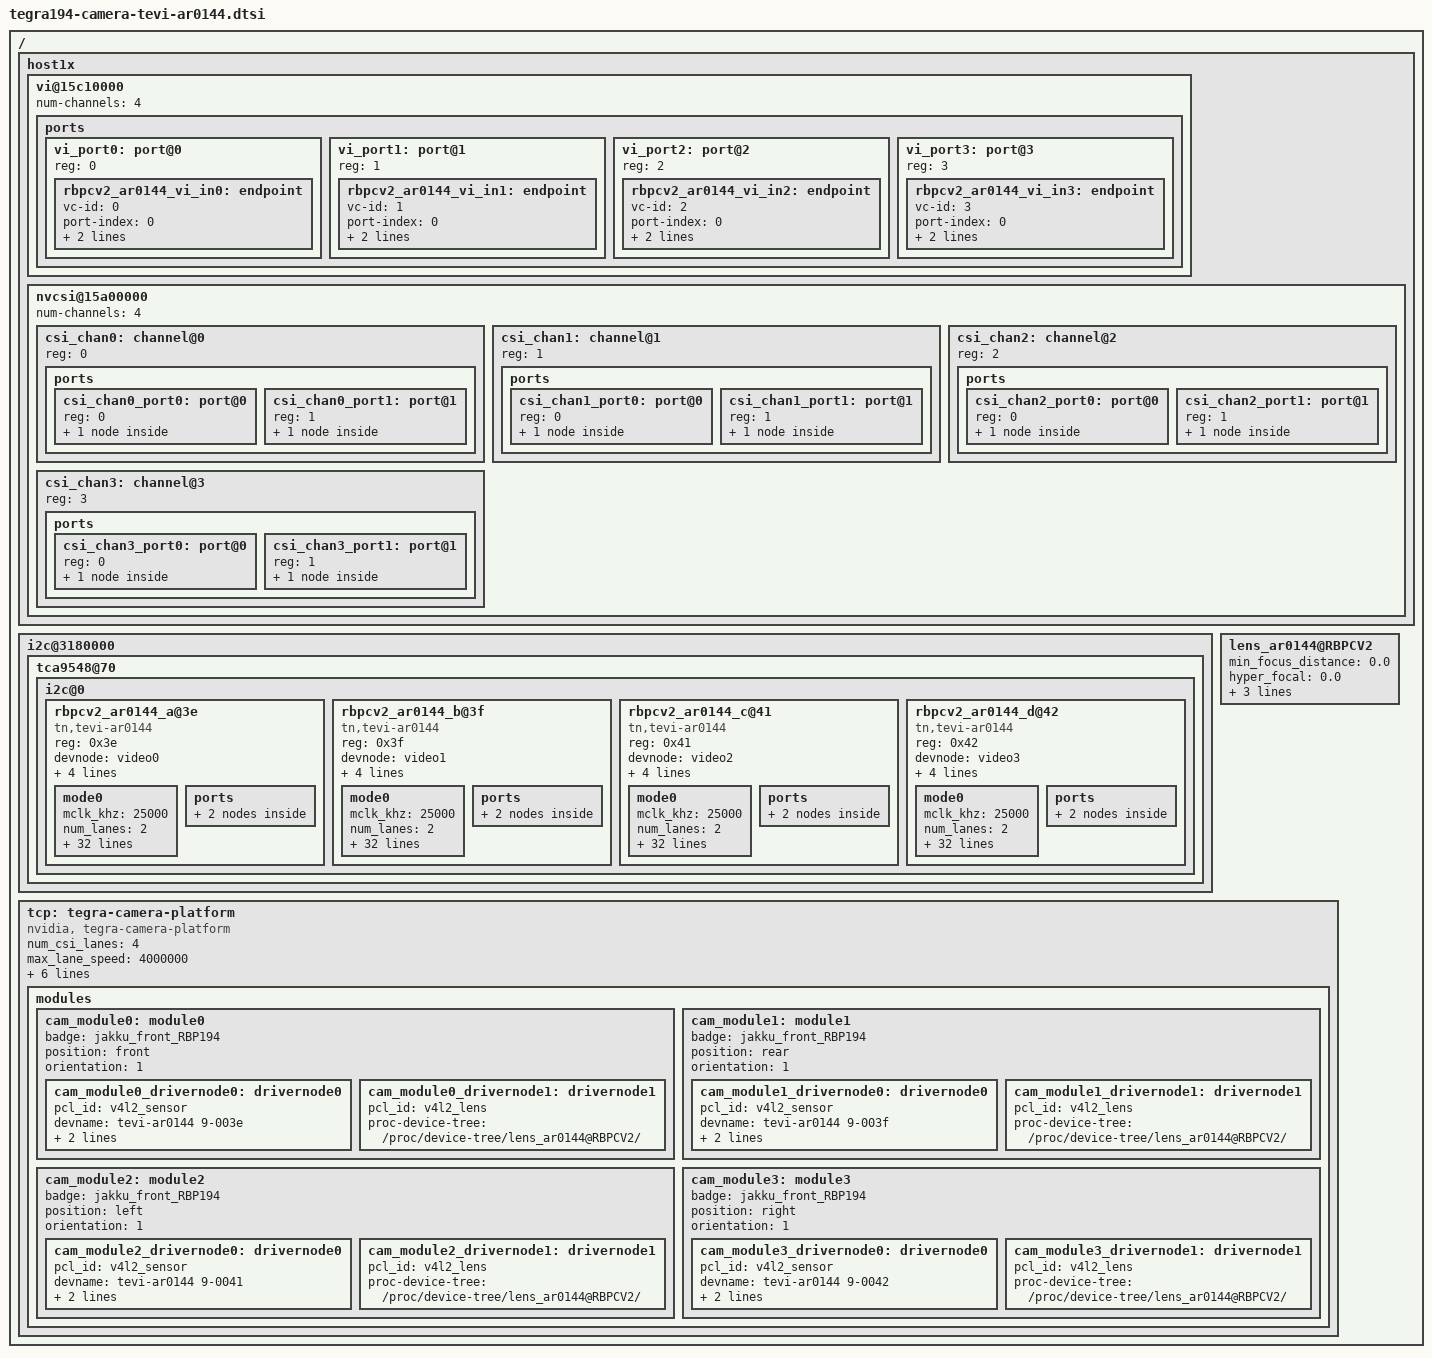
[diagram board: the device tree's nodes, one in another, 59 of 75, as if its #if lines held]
/*
 * Copyright (c) 2018-2020, NVIDIA CORPORATION.  All rights reserved.
 *
 * This program is free software; you can redistribute it and/or modify
 * it under the terms of the GNU General Public License as published by
 * the Free Software Foundation; either version 2 of the License, or
 * (at your option) any later version.
 *
 * This program is distributed in the hope that it will be useful, but WITHOUT
 * ANY WARRANTY; without even the implied warranty of MERCHANTABILITY or
 * FITNESS FOR A PARTICULAR PURPOSE.  See the GNU General Public License for
 * more details.
 *
 * You should have received a copy of the GNU General Public License
 * along with this program.  If not, see <http://www.gnu.org/licenses/>.
 */
#include <dt-bindings/media/camera.h>

/ {
	host1x {
		vi@15c10000  {
			num-channels = <1>;
#ifdef VIZIONLINK_2_CAMERA
			num-channels = <2>;
#endif
#ifdef VIZIONLINK_3_CAMERA
			num-channels = <3>;
#endif
#ifdef VIZIONLINK_4_CAMERA
			num-channels = <4>;
#endif
			ports {
				#address-cells = <1>;
				#size-cells = <0>;
				vi_port0: port@0 {
					reg = <0>;
					rbpcv2_ar0144_vi_in0: endpoint {
						vc-id = <0>;
						port-index = <0>;
						bus-width = <2>;
						remote-endpoint = <&rbpcv2_ar0144_csi_out0>;
					};
				};
#ifdef VIZIONLINK_2_CAMERA
				vi_port1: port@1 {
					reg = <1>;
					rbpcv2_ar0144_vi_in1: endpoint {
						vc-id = <1>;
						port-index = <0>;
						bus-width = <2>;
						remote-endpoint = <&rbpcv2_ar0144_csi_out1>;
					};
				};
#ifdef VIZIONLINK_3_CAMERA
				vi_port2: port@2 {
					reg = <2>;
					rbpcv2_ar0144_vi_in2: endpoint {
						vc-id = <2>;
						port-index = <0>;
						bus-width = <2>;
						remote-endpoint = <&rbpcv2_ar0144_csi_out2>;
					};
				};
#ifdef VIZIONLINK_4_CAMERA
				vi_port3: port@3 {
					reg = <3>;
					rbpcv2_ar0144_vi_in3: endpoint {
						vc-id = <3>;
						port-index = <0>;
						bus-width = <2>;
						remote-endpoint = <&rbpcv2_ar0144_csi_out3>;
					};
				};
#endif//2_CAMERA
#endif//3_CAMERA
#endif//4_CAMERA
			};
		};

		nvcsi@15a00000 {
			num-channels = <1>;
#ifdef VIZIONLINK_2_CAMERA
			num-channels = <2>;
#endif
#ifdef VIZIONLINK_3_CAMERA
			num-channels = <3>;
#endif
#ifdef VIZIONLINK_4_CAMERA
			num-channels = <4>;
#endif
			#address-cells = <1>;
			#size-cells = <0>;
			csi_chan0: channel@0 {
				reg = <0>;
				ports {
					#address-cells = <1>;
					#size-cells = <0>;
					csi_chan0_port0: port@0 {
						reg = <0>;
						rbpcv2_ar0144_csi_in0: endpoint@0 {
							port-index = <0>;
							bus-width = <2>;
							remote-endpoint = <&rbpcv2_ar0144_out0>;
						};
					};
					csi_chan0_port1: port@1 {
						reg = <1>;
						rbpcv2_ar0144_csi_out0: endpoint@1 {
							remote-endpoint = <&rbpcv2_ar0144_vi_in0>;
						};
					};
				};
			};
#ifdef VIZIONLINK_2_CAMERA
			csi_chan1: channel@1 {
				reg = <1>;
				ports {
					#address-cells = <1>;
					#size-cells = <0>;
					csi_chan1_port0: port@0 {
						reg = <0>;
						rbpcv2_ar0144_csi_in1: endpoint@2 {
							port-index = <0>;
							bus-width = <2>;
							remote-endpoint = <&rbpcv2_ar0144_out1>;
						};
					};
					csi_chan1_port1: port@1 {
						reg = <1>;
						rbpcv2_ar0144_csi_out1: endpoint@3 {
							remote-endpoint = <&rbpcv2_ar0144_vi_in1>;
						};
					};
				};
			};
#ifdef VIZIONLINK_3_CAMERA
			csi_chan2: channel@2 {
				reg = <2>;
				ports {
					#address-cells = <1>;
					#size-cells = <0>;
					csi_chan2_port0: port@0 {
						reg = <0>;
						rbpcv2_ar0144_csi_in2: endpoint@4 {
							port-index = <0>;
							bus-width = <2>;
							remote-endpoint = <&rbpcv2_ar0144_out2>;
						};
					};
					csi_chan2_port1: port@1 {
						reg = <1>;
						rbpcv2_ar0144_csi_out2: endpoint@5 {
							remote-endpoint = <&rbpcv2_ar0144_vi_in2>;
						};
					};
				};
			};
#ifdef VIZIONLINK_4_CAMERA
			csi_chan3: channel@3 {
				reg = <3>;
				ports {
					#address-cells = <1>;
					#size-cells = <0>;
					csi_chan3_port0: port@0 {
						reg = <0>;
						rbpcv2_ar0144_csi_in3: endpoint@6 {
							port-index = <0>;
							bus-width = <2>;
							remote-endpoint = <&rbpcv2_ar0144_out3>;
						};
					};
					csi_chan3_port1: port@1 {
						reg = <1>;
						rbpcv2_ar0144_csi_out3: endpoint@7 {
							remote-endpoint = <&rbpcv2_ar0144_vi_in3>;
						};
					};
				};
			};
#endif//2_CAMERA
#endif//3_CAMERA
#endif//4_CAMERA
		};
	};

	i2c@3180000 { /* cam_i2c */
		tca9548@70 {
			i2c@0 {
				rbpcv2_ar0144_a@3e {
					compatible = "tn,tevi-ar0144";
					/* I2C device address */
					reg = <0x3e>;

					/* V4L2 device node location */
					devnode = "video0";

					/* Physical dimensions of sensor */
					physical_w = "3.680";
					physical_h = "2.760";

					sensor_model = "tevi-ar0144";

					use_sensor_mode_id = "true";

					/**
					* ==== Modes ====
					* A modeX node is required to support v4l2 driver
					* implementation with NVIDIA camera software stack
					*
					* == Signal properties ==
					*
					* phy_mode = "";
					* PHY mode used by the MIPI lanes for this device
					*
					* tegra_sinterface = "";
					* CSI Serial interface connected to tegra
					* Incase of virtual HW devices, use virtual
					* For SW emulated devices, use host
					*
					* pix_clk_hz = "";
					* Sensor pixel clock used for calculations like exposure and framerate
					*
					* readout_orientation = "0";
					* Based on camera module orientation.
					* Only change readout_orientation if you specifically
					* Program a different readout order for this mode
					*
					* == Image format Properties ==
					*
					* active_w = "";
					* Pixel active region width
					*
					* active_h = "";
					* Pixel active region height
					*
					* pixel_t = "";
					* The sensor readout pixel pattern
					*
					* line_length = "";
					* Pixel line length (width) for sensor mode.
					*
					* == Source Control Settings ==
					*
					* Gain factor used to convert fixed point integer to float
					* Gain range [min_gain/gain_factor, max_gain/gain_factor]
					* Gain step [step_gain/gain_factor is the smallest step that can be configured]
					* Default gain [Default gain to be initialized for the control.
					*     use min_gain_val as default for optimal results]
					* Framerate factor used to convert fixed point integer to float
					* Framerate range [min_framerate/framerate_factor, max_framerate/framerate_factor]
					* Framerate step [step_framerate/framerate_factor is the smallest step that can be configured]
					* Default Framerate [Default framerate to be initialized for the control.
					*     use max_framerate to get required performance]
					* Exposure factor used to convert fixed point integer to float
					* For convenience use 1 sec = 1000000us as conversion factor
					* Exposure range [min_exp_time/exposure_factor, max_exp_time/exposure_factor]
					* Exposure step [step_exp_time/exposure_factor is the smallest step that can be configured]
					* Default Exposure Time [Default exposure to be initialized for the control.
					*     Set default exposure based on the default_framerate for optimal exposure settings]
					*
					* gain_factor = ""; (integer factor used for floating to fixed point conversion)
					* min_gain_val = ""; (ceil to integer)
					* max_gain_val = ""; (ceil to integer)
					* step_gain_val = ""; (ceil to integer)
					* default_gain = ""; (ceil to integer)
					* Gain limits for mode
					*
					* exposure_factor = ""; (integer factor used for floating to fixed point conversion)
					* min_exp_time = ""; (ceil to integer)
					* max_exp_time = ""; (ceil to integer)
					* step_exp_time = ""; (ceil to integer)
					* default_exp_time = ""; (ceil to integer)
					* Exposure Time limits for mode (sec)
					*
					* framerate_factor = ""; (integer factor used for floating to fixed point conversion)
					* min_framerate = ""; (ceil to integer)
					* max_framerate = ""; (ceil to integer)
					* step_framerate = ""; (ceil to integer)
					* default_framerate = ""; (ceil to integer)
					* Framerate limits for mode (fps)
					*
					* embedded_metadata_height = "";
					* Sensor embedded metadata height in units of rows.
					* If sensor does not support embedded metadata value should be 0.
					*/
					mode0 { /* AR0144_MODE_1280x800_30FPS */
							mclk_khz = "25000";
							num_lanes = "2";
							tegra_sinterface = "serial_a";
							vc_id = "0";
							phy_mode = "DPHY";
							discontinuous_clk = "no";
							dpcm_enable = "false";
							cil_settletime = "0";

							active_w = "1280";
							active_h = "800";
							pixel_t = "yuv_uyvy16";
							readout_orientation = "0";
							line_length = "1100";
							inherent_gain = "1";
							// mclk_multiplier = "9.33";
							// pix_clk_hz = "182400000";
							pix_clk_hz = "100000000";
							serdes_pix_clk_hz = "4000000000";

							gain_factor = "16";
							framerate_factor = "1000000";
							exposure_factor = "1000000";
							min_gain_val = "16"; /* 1.00x */
							max_gain_val = "170"; /* 10.66x */
							step_gain_val = "1";
							default_gain = "16"; /* 1.00x */
							min_hdr_ratio = "1";
							max_hdr_ratio = "1";
							min_framerate = "2000000"; /* 2.0 fps */
							max_framerate = "15000000"; /* 21.0 fps */
							step_framerate = "1";
							default_framerate = "15000000"; /* 21.0 fps */
							min_exp_time = "13"; /* us */
							max_exp_time = "683709"; /* us */
							step_exp_time = "1";
							default_exp_time = "2495"; /* us */

							embedded_metadata_height = "0";
					};

					ports {
						#address-cells = <1>;
						#size-cells = <0>;
						port@0 {
							reg = <0>;
							rbpcv2_ar0144_out0: endpoint {
									vc-id = <0>;
								port-index = <0>;
								bus-width = <2>;
								remote-endpoint = <&rbpcv2_ar0144_csi_in0>;
							};
						};
					};
				};
#ifdef VIZIONLINK_2_CAMERA
				rbpcv2_ar0144_b@3f {
					compatible = "tn,tevi-ar0144";
					/* I2C device address */
					reg = <0x3f>;

					/* V4L2 device node location */
					devnode = "video1";

					/* Physical dimensions of sensor */
					physical_w = "3.680";
					physical_h = "2.760";

					sensor_model = "tevi-ar0144";

					use_sensor_mode_id = "true";

					/**
					* ==== Modes ====
					* A modeX node is required to support v4l2 driver
					* implementation with NVIDIA camera software stack
					*
					* == Signal properties ==
					*
					* phy_mode = "";
					* PHY mode used by the MIPI lanes for this device
					*
					* tegra_sinterface = "";
					* CSI Serial interface connected to tegra
					* Incase of virtual HW devices, use virtual
					* For SW emulated devices, use host
					*
					* pix_clk_hz = "";
					* Sensor pixel clock used for calculations like exposure and framerate
					*
					* readout_orientation = "0";
					* Based on camera module orientation.
					* Only change readout_orientation if you specifically
					* Program a different readout order for this mode
					*
					* == Image format Properties ==
					*
					* active_w = "";
					* Pixel active region width
					*
					* active_h = "";
					* Pixel active region height
					*
					* pixel_t = "";
					* The sensor readout pixel pattern
					*
					* line_length = "";
					* Pixel line length (width) for sensor mode.
					*
					* == Source Control Settings ==
					*
					* Gain factor used to convert fixed point integer to float
					* Gain range [min_gain/gain_factor, max_gain/gain_factor]
					* Gain step [step_gain/gain_factor is the smallest step that can be configured]
					* Default gain [Default gain to be initialized for the control.
					*     use min_gain_val as default for optimal results]
					* Framerate factor used to convert fixed point integer to float
					* Framerate range [min_framerate/framerate_factor, max_framerate/framerate_factor]
					* Framerate step [step_framerate/framerate_factor is the smallest step that can be configured]
					* Default Framerate [Default framerate to be initialized for the control.
					*     use max_framerate to get required performance]
					* Exposure factor used to convert fixed point integer to float
					* For convenience use 1 sec = 1000000us as conversion factor
					* Exposure range [min_exp_time/exposure_factor, max_exp_time/exposure_factor]
					* Exposure step [step_exp_time/exposure_factor is the smallest step that can be configured]
					* Default Exposure Time [Default exposure to be initialized for the control.
					*     Set default exposure based on the default_framerate for optimal exposure settings]
					*
					* gain_factor = ""; (integer factor used for floating to fixed point conversion)
					* min_gain_val = ""; (ceil to integer)
					* max_gain_val = ""; (ceil to integer)
					* step_gain_val = ""; (ceil to integer)
					* default_gain = ""; (ceil to integer)
					* Gain limits for mode
					*
					* exposure_factor = ""; (integer factor used for floating to fixed point conversion)
					* min_exp_time = ""; (ceil to integer)
					* max_exp_time = ""; (ceil to integer)
					* step_exp_time = ""; (ceil to integer)
					* default_exp_time = ""; (ceil to integer)
					* Exposure Time limits for mode (sec)
					*
					* framerate_factor = ""; (integer factor used for floating to fixed point conversion)
					* min_framerate = ""; (ceil to integer)
					* max_framerate = ""; (ceil to integer)
					* step_framerate = ""; (ceil to integer)
					* default_framerate = ""; (ceil to integer)
					* Framerate limits for mode (fps)
					*
					* embedded_metadata_height = "";
					* Sensor embedded metadata height in units of rows.
					* If sensor does not support embedded metadata value should be 0.
					*/
					mode0 { /* AR0144_MODE_1280x800_30FPS */
							mclk_khz = "25000";
							num_lanes = "2";
							tegra_sinterface = "serial_a";
							vc_id = "1";
							phy_mode = "DPHY";
							discontinuous_clk = "no";
							dpcm_enable = "false";
							cil_settletime = "0";

							active_w = "1280";
							active_h = "800";
							pixel_t = "yuv_uyvy16";
							readout_orientation = "0";
							line_length = "1100";
							inherent_gain = "1";
							// mclk_multiplier = "9.33";
							// pix_clk_hz = "182400000";
							pix_clk_hz = "100000000";
							serdes_pix_clk_hz = "4000000000";

							gain_factor = "16";
							framerate_factor = "1000000";
							exposure_factor = "1000000";
							min_gain_val = "16"; /* 1.00x */
							max_gain_val = "170"; /* 10.66x */
							step_gain_val = "1";
							default_gain = "16"; /* 1.00x */
							min_hdr_ratio = "1";
							max_hdr_ratio = "1";
							min_framerate = "2000000"; /* 2.0 fps */
							max_framerate = "15000000"; /* 21.0 fps */
							step_framerate = "1";
							default_framerate = "15000000"; /* 21.0 fps */
							min_exp_time = "13"; /* us */
							max_exp_time = "683709"; /* us */
							step_exp_time = "1";
							default_exp_time = "2495"; /* us */

							embedded_metadata_height = "0";
					};

					ports {
						#address-cells = <1>;
						#size-cells = <0>;
						port@0 {
							reg = <0>;
							rbpcv2_ar0144_out1: endpoint {
									vc-id = <1>;
								port-index = <0>;
								bus-width = <2>;
								remote-endpoint = <&rbpcv2_ar0144_csi_in1>;
							};
						};
					};
				};
#ifdef VIZIONLINK_3_CAMERA
				rbpcv2_ar0144_c@41 {
					compatible = "tn,tevi-ar0144";
					/* I2C device address */
					reg = <0x41>;

					/* V4L2 device node location */
					devnode = "video2";

					/* Physical dimensions of sensor */
					physical_w = "3.680";
					physical_h = "2.760";

					sensor_model = "tevi-ar0144";

					use_sensor_mode_id = "true";

					/**
					* ==== Modes ====
					* A modeX node is required to support v4l2 driver
					* implementation with NVIDIA camera software stack
					*
					* == Signal properties ==
					*
					* phy_mode = "";
					* PHY mode used by the MIPI lanes for this device
					*
					* tegra_sinterface = "";
					* CSI Serial interface connected to tegra
					* Incase of virtual HW devices, use virtual
					* For SW emulated devices, use host
					*
					* pix_clk_hz = "";
					* Sensor pixel clock used for calculations like exposure and framerate
					*
					* readout_orientation = "0";
					* Based on camera module orientation.
					* Only change readout_orientation if you specifically
					* Program a different readout order for this mode
					*
					* == Image format Properties ==
					*
					* active_w = "";
					* Pixel active region width
					*
					* active_h = "";
					* Pixel active region height
					*
					* pixel_t = "";
					* The sensor readout pixel pattern
					*
					* line_length = "";
					* Pixel line length (width) for sensor mode.
					*
					* == Source Control Settings ==
					*
					* Gain factor used to convert fixed point integer to float
					* Gain range [min_gain/gain_factor, max_gain/gain_factor]
					* Gain step [step_gain/gain_factor is the smallest step that can be configured]
					* Default gain [Default gain to be initialized for the control.
					*     use min_gain_val as default for optimal results]
					* Framerate factor used to convert fixed point integer to float
					* Framerate range [min_framerate/framerate_factor, max_framerate/framerate_factor]
					* Framerate step [step_framerate/framerate_factor is the smallest step that can be configured]
					* Default Framerate [Default framerate to be initialized for the control.
					*     use max_framerate to get required performance]
					* Exposure factor used to convert fixed point integer to float
					* For convenience use 1 sec = 1000000us as conversion factor
					* Exposure range [min_exp_time/exposure_factor, max_exp_time/exposure_factor]
					* Exposure step [step_exp_time/exposure_factor is the smallest step that can be configured]
					* Default Exposure Time [Default exposure to be initialized for the control.
					*     Set default exposure based on the default_framerate for optimal exposure settings]
					*
					* gain_factor = ""; (integer factor used for floating to fixed point conversion)
					* min_gain_val = ""; (ceil to integer)
					* max_gain_val = ""; (ceil to integer)
					* step_gain_val = ""; (ceil to integer)
					* default_gain = ""; (ceil to integer)
					* Gain limits for mode
					*
					* exposure_factor = ""; (integer factor used for floating to fixed point conversion)
					* min_exp_time = ""; (ceil to integer)
					* max_exp_time = ""; (ceil to integer)
					* step_exp_time = ""; (ceil to integer)
					* default_exp_time = ""; (ceil to integer)
					* Exposure Time limits for mode (sec)
					*
					* framerate_factor = ""; (integer factor used for floating to fixed point conversion)
					* min_framerate = ""; (ceil to integer)
					* max_framerate = ""; (ceil to integer)
					* step_framerate = ""; (ceil to integer)
					* default_framerate = ""; (ceil to integer)
					* Framerate limits for mode (fps)
					*
					* embedded_metadata_height = "";
					* Sensor embedded metadata height in units of rows.
					* If sensor does not support embedded metadata value should be 0.
					*/
					mode0 { /* AR0144_MODE_1280x800_30FPS */
							mclk_khz = "25000";
							num_lanes = "2";
							tegra_sinterface = "serial_a";
							vc_id = "2";
							phy_mode = "DPHY";
							discontinuous_clk = "no";
							dpcm_enable = "false";
							cil_settletime = "0";

							active_w = "1280";
							active_h = "800";
							pixel_t = "yuv_uyvy16";
							readout_orientation = "0";
							line_length = "1100";
							inherent_gain = "1";
							// mclk_multiplier = "9.33";
							// pix_clk_hz = "182400000";
							pix_clk_hz = "100000000";
							serdes_pix_clk_hz = "4000000000";

							gain_factor = "16";
							framerate_factor = "1000000";
							exposure_factor = "1000000";
							min_gain_val = "16"; /* 1.00x */
							max_gain_val = "170"; /* 10.66x */
							step_gain_val = "1";
							default_gain = "16"; /* 1.00x */
							min_hdr_ratio = "1";
							max_hdr_ratio = "1";
							min_framerate = "2000000"; /* 2.0 fps */
							max_framerate = "15000000"; /* 21.0 fps */
							step_framerate = "1";
							default_framerate = "15000000"; /* 21.0 fps */
							min_exp_time = "13"; /* us */
							max_exp_time = "683709"; /* us */
							step_exp_time = "1";
							default_exp_time = "2495"; /* us */

							embedded_metadata_height = "0";
					};

					ports {
						#address-cells = <1>;
						#size-cells = <0>;
						port@0 {
							reg = <0>;
							rbpcv2_ar0144_out2: endpoint {
									vc-id = <2>;
								port-index = <0>;
								bus-width = <2>;
								remote-endpoint = <&rbpcv2_ar0144_csi_in2>;
							};
						};
					};
				};
#ifdef VIZIONLINK_4_CAMERA
				rbpcv2_ar0144_d@42 {
					compatible = "tn,tevi-ar0144";
					/* I2C device address */
					reg = <0x42>;

					/* V4L2 device node location */
					devnode = "video3";

					/* Physical dimensions of sensor */
					physical_w = "3.680";
					physical_h = "2.760";

					sensor_model = "tevi-ar0144";

					use_sensor_mode_id = "true";

					/**
					* ==== Modes ====
					* A modeX node is required to support v4l2 driver
					* implementation with NVIDIA camera software stack
					*
					* == Signal properties ==
					*
					* phy_mode = "";
					* PHY mode used by the MIPI lanes for this device
					*
					* tegra_sinterface = "";
					* CSI Serial interface connected to tegra
					* Incase of virtual HW devices, use virtual
					* For SW emulated devices, use host
					*
					* pix_clk_hz = "";
					* Sensor pixel clock used for calculations like exposure and framerate
					*
					* readout_orientation = "0";
					* Based on camera module orientation.
					* Only change readout_orientation if you specifically
					* Program a different readout order for this mode
					*
					* == Image format Properties ==
					*
					* active_w = "";
					* Pixel active region width
					*
					* active_h = "";
					* Pixel active region height
					*
					* pixel_t = "";
					* The sensor readout pixel pattern
					*
					* line_length = "";
					* Pixel line length (width) for sensor mode.
					*
					* == Source Control Settings ==
					*
					* Gain factor used to convert fixed point integer to float
					* Gain range [min_gain/gain_factor, max_gain/gain_factor]
					* Gain step [step_gain/gain_factor is the smallest step that can be configured]
					* Default gain [Default gain to be initialized for the control.
					*     use min_gain_val as default for optimal results]
					* Framerate factor used to convert fixed point integer to float
					* Framerate range [min_framerate/framerate_factor, max_framerate/framerate_factor]
					* Framerate step [step_framerate/framerate_factor is the smallest step that can be configured]
					* Default Framerate [Default framerate to be initialized for the control.
					*     use max_framerate to get required performance]
					* Exposure factor used to convert fixed point integer to float
					* For convenience use 1 sec = 1000000us as conversion factor
					* Exposure range [min_exp_time/exposure_factor, max_exp_time/exposure_factor]
					* Exposure step [step_exp_time/exposure_factor is the smallest step that can be configured]
					* Default Exposure Time [Default exposure to be initialized for the control.
					*     Set default exposure based on the default_framerate for optimal exposure settings]
					*
					* gain_factor = ""; (integer factor used for floating to fixed point conversion)
					* min_gain_val = ""; (ceil to integer)
					* max_gain_val = ""; (ceil to integer)
					* step_gain_val = ""; (ceil to integer)
					* default_gain = ""; (ceil to integer)
					* Gain limits for mode
					*
					* exposure_factor = ""; (integer factor used for floating to fixed point conversion)
					* min_exp_time = ""; (ceil to integer)
					* max_exp_time = ""; (ceil to integer)
					* step_exp_time = ""; (ceil to integer)
					* default_exp_time = ""; (ceil to integer)
					* Exposure Time limits for mode (sec)
					*
					* framerate_factor = ""; (integer factor used for floating to fixed point conversion)
					* min_framerate = ""; (ceil to integer)
					* max_framerate = ""; (ceil to integer)
					* step_framerate = ""; (ceil to integer)
					* default_framerate = ""; (ceil to integer)
					* Framerate limits for mode (fps)
					*
					* embedded_metadata_height = "";
					* Sensor embedded metadata height in units of rows.
					* If sensor does not support embedded metadata value should be 0.
					*/
					mode0 { /* AR0144_MODE_1280x800_30FPS */
							mclk_khz = "25000";
							num_lanes = "2";
							tegra_sinterface = "serial_a";
							vc_id = "3";
							phy_mode = "DPHY";
							discontinuous_clk = "no";
							dpcm_enable = "false";
							cil_settletime = "0";

							active_w = "1280";
							active_h = "800";
							pixel_t = "yuv_uyvy16";
							readout_orientation = "0";
							line_length = "1100";
							inherent_gain = "1";
							// mclk_multiplier = "9.33";
							// pix_clk_hz = "182400000";
							pix_clk_hz = "100000000";
							serdes_pix_clk_hz = "4000000000";

							gain_factor = "16";
							framerate_factor = "1000000";
							exposure_factor = "1000000";
							min_gain_val = "16"; /* 1.00x */
							max_gain_val = "170"; /* 10.66x */
							step_gain_val = "1";
							default_gain = "16"; /* 1.00x */
							min_hdr_ratio = "1";
							max_hdr_ratio = "1";
							min_framerate = "2000000"; /* 2.0 fps */
							max_framerate = "15000000"; /* 21.0 fps */
							step_framerate = "1";
							default_framerate = "15000000"; /* 21.0 fps */
							min_exp_time = "13"; /* us */
							max_exp_time = "683709"; /* us */
							step_exp_time = "1";
							default_exp_time = "2495"; /* us */

							embedded_metadata_height = "0";
					};

					ports {
						#address-cells = <1>;
						#size-cells = <0>;
						port@0 {
							reg = <0>;
							rbpcv2_ar0144_out3: endpoint {
									vc-id = <3>;
								port-index = <0>;
								bus-width = <2>;
								remote-endpoint = <&rbpcv2_ar0144_csi_in3>;
							};
						};
					};
				};
#endif//2_CAMERA
#endif//3_CAMERA
#endif//4_CAMERA
			};
		};
        };
        
	lens_ar0144@RBPCV2 {
		min_focus_distance = "0.0";
		hyper_focal = "0.0";
		focal_length = "3.04";
		f_number = "2.0";
		aperture = "0.0";
	};
};
/ {
	tcp: tegra-camera-platform {
		compatible = "nvidia, tegra-camera-platform";
		/**
		* Physical settings to calculate max ISO BW
		*
		* num_csi_lanes = <>;
		* Total number of CSI lanes when all cameras are active
		*
		* max_lane_speed = <>;
		* Max lane speed in Kbit/s
		*
		* min_bits_per_pixel = <>;
		* Min bits per pixel
		*
		* vi_peak_byte_per_pixel = <>;
		* Max byte per pixel for the VI ISO case
		*
		* vi_bw_margin_pct = <>;
		* Vi bandwidth margin in percentage
		*
		* max_pixel_rate = <>;
		* Max pixel rate in Kpixel/s for the ISP ISO case
		*
		* isp_peak_byte_per_pixel = <>;
		* Max byte per pixel for the ISP ISO case
		*
		* isp_bw_margin_pct = <>;
		* Isp bandwidth margin in percentage
		*/
		num_csi_lanes = <4>;
		max_lane_speed = <4000000>;
		min_bits_per_pixel = <10>;
		vi_peak_byte_per_pixel = <2>;
		vi_bw_margin_pct = <25>;
		max_pixel_rate = <240000>;
		isp_peak_byte_per_pixel = <5>;
		isp_bw_margin_pct = <25>;

		/**
		 * The general guideline for naming badge_info contains 3 parts, and is as follows,
		 * The first part is the camera_board_id for the module; if the module is in a FFD
		 * platform, then use the platform name for this part.
		 * The second part contains the position of the module, ex. "rear" or "front".
		 * The third part contains the last 6 characters of a part number which is found
		 * in the module's specsheet from the vendor.
		 */
		modules {
			cam_module0: module0 {
				badge = "jakku_front_RBP194";
				position = "front";
				orientation = "1";
				cam_module0_drivernode0: drivernode0 {
					pcl_id = "v4l2_sensor";
					devname = "tevi-ar0144 9-003e";
					proc-device-tree = "/proc/device-tree/i2c@3180000/tca9546@70/i2c@0/rbpcv2_ar0144_a@3e";
				};
				cam_module0_drivernode1: drivernode1 {
					pcl_id = "v4l2_lens";
					proc-device-tree = "/proc/device-tree/lens_ar0144@RBPCV2/";
				};
			};
#ifdef VIZIONLINK_2_CAMERA
			cam_module1: module1 {
				badge = "jakku_front_RBP194";
				position = "rear";
				orientation = "1";
				cam_module1_drivernode0: drivernode0 {
					pcl_id = "v4l2_sensor";
					devname = "tevi-ar0144 9-003f";
					proc-device-tree = "/proc/device-tree/i2c@3180000/tca9546@70/i2c@0/rbpcv2_ar0144_b@3f";
				};
				cam_module1_drivernode1: drivernode1 {
					pcl_id = "v4l2_lens";
					proc-device-tree = "/proc/device-tree/lens_ar0144@RBPCV2/";
				};
			};
#ifdef VIZIONLINK_3_CAMERA
			cam_module2: module2 {
				badge = "jakku_front_RBP194";
				position = "left";
				orientation = "1";
				cam_module2_drivernode0: drivernode0 {
					pcl_id = "v4l2_sensor";
					devname = "tevi-ar0144 9-0041";
					proc-device-tree = "/proc/device-tree/i2c@3180000/tca9546@70/i2c@0/rbpcv2_ar0144_b@41";
				};
				cam_module2_drivernode1: drivernode1 {
					pcl_id = "v4l2_lens";
					proc-device-tree = "/proc/device-tree/lens_ar0144@RBPCV2/";
				};
			};
#ifdef VIZIONLINK_4_CAMERA
			cam_module3: module3 {
				badge = "jakku_front_RBP194";
				position = "right";
				orientation = "1";
				cam_module3_drivernode0: drivernode0 {
					pcl_id = "v4l2_sensor";
					devname = "tevi-ar0144 9-0042";
					proc-device-tree = "/proc/device-tree/i2c@3180000/tca9546@70/i2c@0/rbpcv2_ar0144_b@42";
				};
				cam_module3_drivernode1: drivernode1 {
					pcl_id = "v4l2_lens";
					proc-device-tree = "/proc/device-tree/lens_ar0144@RBPCV2/";
				};
			};

#endif//2_CAMERA
#endif//3_CAMERA
#endif//4_CAMERA
		};
	};
};
